# DMASS_BCDMA_0_BCDMA_BCRT_4C000000h register map
Vendor: Texas Instruments
Peripheral module from a debugger description file (folder AM275x).
Registers are 32-bit, access not given, reset 0x0 unless marked. A register's access mark holds for its fields unless they carry their own. Offsets are as the file gives them; lines under a group give offsets from that group; [hi:lo] are bit positions; {n}, {i} and the like mark numbered series; 'fields as' and 'values as' point back to an identical list; <NAME> marks a mode.

## bcdma_bcrt
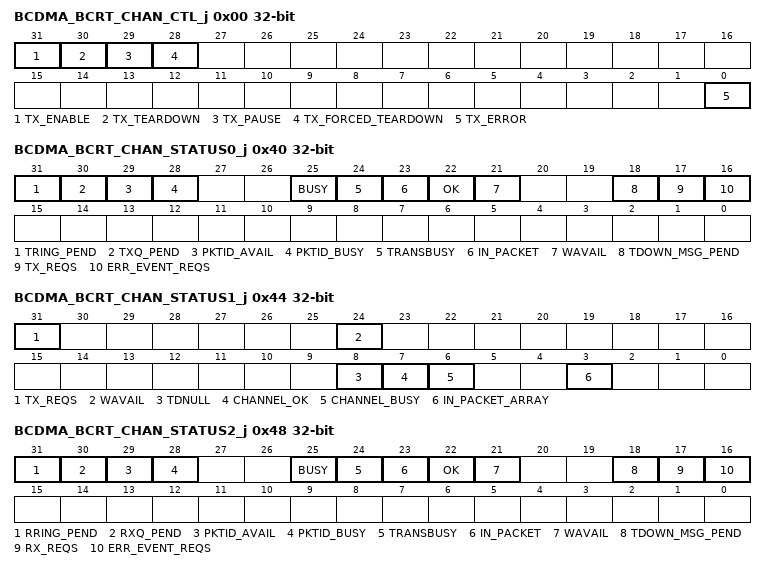
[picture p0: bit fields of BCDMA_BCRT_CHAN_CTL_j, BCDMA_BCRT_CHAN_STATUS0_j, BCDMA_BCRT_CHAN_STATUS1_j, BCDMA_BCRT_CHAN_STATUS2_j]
0x00 BCDMA_BCRT_CHAN_CTL_j access per field — The Tx Channel Realtime Control Register contains real-time control and status information for the Tx DMA channel. The fields in this register can safely be changed while the channel is in operation.
  [31] TX_ENABLE rw — This field enables or disables the channel. Disabling a channel halts operation on the channel after the current block transfer is completed. Disabling a channel in the middle of a packet transfer may result in underflow conditions in the attached application block and data loss. When a channel is disabled, the implementation may choose to reset all state for the channel. The pause bit should be asserted instead of clearing enable directly if the intent is to temporarily pause the channel. This field is encoded as follows: 0 = channel is disabled 1 = channel is enabled This field will be cleared by HW after a teardown is requested to indicate that the channel teardown is complete. Reset Source: rst_mod_g_rst_n
  [30] TX_TEARDOWN rw — Channel teardown: Setting this bit will request the channel to be torn down. This field will remain set after a channel teardown is complete. Reset Source: rst_mod_g_rst_n
  [29] TX_PAUSE rw — Channel pause: Setting this bit will cause the channel to pause processing immediately. Reset Source: rst_mod_g_rst_n
  [28] TX_FORCED_TEARDOWN rw — Channel forced teardown: Setting this bit will cause the channel to stop waiting on trigger events. When this bit is set, the implementation may choose to bypass data transfers and event generation. This bit is a modifier to the normal tx_teardown and is intended to flush the channel to recover any descriptor or TR references which are currently being held by the BCDMA even if the trigger source is no longer functioning. Use og this bit is considered a 'catastrophic' condition and it is assumed that SW will need to perform some re-initialization in the system to re-align events, data buffers, etc. This bit should be set in addition to the tx_teardown bit in order to cause a forced teardown. This field will remain set after a channel teardown is complete. Reset Source: rst_mod_g_rst_n
  [0] TX_ERROR ro — Channel error: This bit will be set anytime an error has occurred on the channel. This bit is cleared by writing back a 0. Reset Source: rst_mod_g_rst_n
0x08 BCDMA_BCRT_CHAN_SWTRIG_j — The Software Trigger Register provides a mechanism by which software can directly trigger the channel in a secure way. This register is only used when the tx_chan_type is configured as a Third Party DMA channel. This register has no function when the channel is configured for packet mode transfers. A write to this register will cause an event to be sent to this channel.
  [0] TRIGGER — Trigger: writing this bit with a value of 1 will cause the trigger event to be sent to this channel Reset Source: rst_mod_g_rst_n (access NA/W)
0x40 BCDMA_BCRT_CHAN_STATUS0_j ro — The Status Register provides a read only view of channel status bits.
  [31] TRING_PEND — The channel ring has a descriptor Reset Source: rst_mod_g_rst_n
  [30] TXQ_PEND — The channel fifo is available Reset Source: rst_mod_g_rst_n
  [29] PKTID_AVAIL — The channel has an available packet id Reset Source: rst_mod_g_rst_n
  [28] PKTID_BUSY — There is an outstanding pktid for the channel Reset Source: rst_mod_g_rst_n
  [25] BUSY — The channel is busy Reset Source: rst_mod_g_rst_n
  [24] TRANSBUSY — The channel has an outstanding transaction Reset Source: rst_mod_g_rst_n
  [23] IN_PACKET — The channel is currently in a packet Reset Source: rst_mod_g_rst_n
  [22] OK — The channel is ready to be scheduled Reset Source: rst_mod_g_rst_n
  [21] WAVAIL — The fifo for the channel has space to place a burst size entry Reset Source: rst_mod_g_rst_n
  [18] TDOWN_MSG_PEND — A teardown message is pending Reset Source: rst_mod_g_rst_n
  [17] TX_REQS — The channel is sending a schedule request Reset Source: rst_mod_g_rst_n
  [16] ERR_EVENT_REQS — The channel is trying to schedule an error event Reset Source: rst_mod_g_rst_n
0x44 BCDMA_BCRT_CHAN_STATUS1_j ro — The Status Register provides a read only view of channel status bits.
  [31] TX_REQS — The channel is sending a schedule request Reset Source: rst_mod_g_rst_n
  [24] WAVAIL — The fifo has space for a burst size Reset Source: rst_mod_g_rst_n
  [8] TDNULL — Channel is trying to teardown and has met conditions Reset Source: rst_mod_g_rst_n
  [7] CHANNEL_OK — Channel is trying to schedule a transaction Reset Source: rst_mod_g_rst_n
  [6] CHANNEL_BUSY — The channel is active Reset Source: rst_mod_g_rst_n
  [3] IN_PACKET_ARRAY — The channel is in a packet Reset Source: rst_mod_g_rst_n
0x48 BCDMA_BCRT_CHAN_STATUS2_j ro — The Status Register provides a read only view of channel status bits.
  [31] RRING_PEND — The channel ring has a descriptor Reset Source: rst_mod_g_rst_n
  [30] RXQ_PEND — The channel fifo is available Reset Source: rst_mod_g_rst_n
  [29] PKTID_AVAIL — The channel has an available packet id Reset Source: rst_mod_g_rst_n
  [28] PKTID_BUSY — There is an outstanding pktid for the channel Reset Source: rst_mod_g_rst_n
  [25] BUSY — The channel is busy Reset Source: rst_mod_g_rst_n
  [24] TRANSBUSY — The channel has an outstanding transaction Reset Source: rst_mod_g_rst_n
  [23] IN_PACKET — The channel is currently in a packet Reset Source: rst_mod_g_rst_n
  [22] OK — The channel is ready to be scheduled Reset Source: rst_mod_g_rst_n
  [21] WAVAIL — The fifo for the channel has space to place a burst size entry Reset Source: rst_mod_g_rst_n
  [18] TDOWN_MSG_PEND — A teardown message is pending Reset Source: rst_mod_g_rst_n
  [17] RX_REQS — The channel is sending a schedule request Reset Source: rst_mod_g_rst_n
  [16] ERR_EVENT_REQS — The channel is trying to schedule an error event Reset Source: rst_mod_g_rst_n
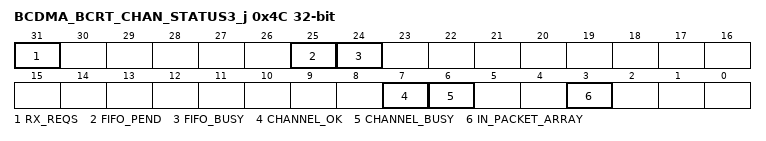
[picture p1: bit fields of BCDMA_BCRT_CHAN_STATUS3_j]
0x4C BCDMA_BCRT_CHAN_STATUS3_j ro — The Status Register provides a read only view of channel status bits.
  [31] RX_REQS — The channel is sending a schedule request Reset Source: rst_mod_g_rst_n
  [25] FIFO_PEND — The FIFO has enough data for a burst Reset Source: rst_mod_g_rst_n
  [24] FIFO_BUSY — The fifo has data Reset Source: rst_mod_g_rst_n
  [7] CHANNEL_OK — Reserved Reset Source: rst_mod_g_rst_n
  [6] CHANNEL_BUSY — Reserved Reset Source: rst_mod_g_rst_n
  [3] IN_PACKET_ARRAY — Reserved Reset Source: rst_mod_g_rst_n
0x80 BCDMA_BCRT_CHAN_STDATA_j_k — The State Data Registers contain the current working state of the Tx DMA channel. These registers are provided so that the Host can determine the potential cause of an error or exception condition which was reported by the channel. These registers should not be accessed without reason while the BCDMA is operating as accesses will cause performance to decrease as these MMRs are just providing a window into the actual state RAM
  [31:0] STATE_INFO — See Tx state mapping table Reset Source: rst_mod_g_rst_n (access R/NA)
0x100 BCDMA_BCRT_CHAN_STDATAW_j_k rw — The State Data Registers contain the current working state of the Rx DMA channel. These registers are provided so that the Host can determine the potential cause of an error or exception condition which was reported by the channel. These registers should not be accessed without reason while the BCDMA is operating as accesses will cause performance to decrease as these MMRs are just providing a window into the actual state RAM
  [31:0] STATE_INFO — See Rx state mapping table Reset Source: rst_mod_g_rst_n
0x400 BCDMA_BCRT_CHAN_PCNT_j — The statistics registers are supplied to give software applications operational progress status for the channel.
  [31:0] PCNT — Current completed packet count for the channel. Reset Source: rst_mod_g_rst_n (access R/WTD)
0x408 BCDMA_BCRT_CHAN_BCNT_j — The statistics registers are supplied to give software applications operational progress status for the channel.
  [31:0] BCNT — Current completed payload byte count for the channel. Reset Source: rst_mod_g_rst_n (access R/WTD)
0x410 BCDMA_BCRT_CHAN_SBCNT_j — The statistics registers are supplied to give software applications operational progress status for the channel.
  [31:0] SBCNT — Current started byte count for the channel. Reset Source: rst_mod_g_rst_n (access R/WTD)
